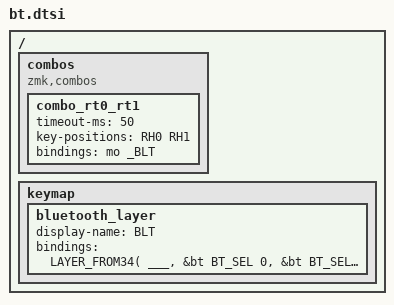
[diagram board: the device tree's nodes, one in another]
#include <dt-bindings/zmk/bt.h>

#define _BLT 5

/ {
    combos {
        compatible = "zmk,combos";

        // both right thumbs → bluetooth layer
        combo_rt0_rt1 {
            timeout-ms = <50>;
            key-positions = <RH0 RH1>;
            bindings = <&mo _BLT>;
        };
    };

    keymap {
        bluetooth_layer {
            display-name = "BLT";
//  ╭─────┬─────┬─────┬─────┬─────╮    ╭─────┬─────┬─────┬─────┬─────╮
//  │     │ bt1 │ bt2 │ bt3 │     │    │     │     │     │     │     │
//  ├─────┼─────┼─────┼─────┼─────┤    ├─────┼─────┼─────┼─────┼─────┤
//  │     │     │ prv │ nxt │ clr │    │     │     │     │     │     │
//  ├─────┼─────┼─────┼─────┼─────┤    ├─────┼─────┼─────┼─────┼─────┤
//  │     │     │     │     │     │    │     │     │     │     │     │
//  ╰─────┴─────┴─────┼─────┼─────┤    ├─────┼─────┼─────┴─────┴─────╯
//                    │     │     │    │     │     │
//                    ╰─────┴─────╯    ╰─────┴─────╯
            bindings = <LAYER_FROM34(
                ___,  &bt BT_SEL 0,  &bt BT_SEL 1,  &bt BT_SEL 2,  ___,  ___,  ___,  ___,  ___,  ___,
                ___,  ___,           &bt BT_PRV,    &bt BT_NXT,    &bt BT_CLR,  ___,  ___,  ___,  ___,  ___,
                ___,  ___,           ___,           ___,           ___,  ___,  ___,  ___,  ___,  ___,
                ___,  ___,  ___,  ___
            )>;
        };
    };
};
